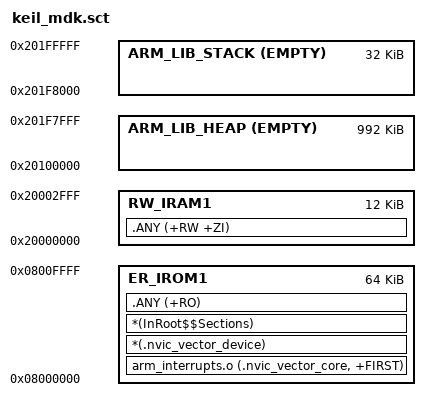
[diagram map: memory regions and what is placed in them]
; *************************************************************
; *** Scatter-Loading Description File generated by uVision ***
; *************************************************************


LR_IROM1 0x08000000 0x00010000  {    ; load region size_region
  ER_IROM1 0x08000000 0x00010000  {  ; load address = execution address
   arm_interrupts.o (.nvic_vector_core, +FIRST)
   *(.nvic_vector_device)
   *(InRoot$$Sections)
   .ANY (+RO)
  }
  RW_IRAM1 0x20000000 0x00003000  {  ; RW data
   .ANY (+RW +ZI)
  }
  ARM_LIB_HEAP 0x20100000 EMPTY 0x100000-0x8000 {} ; Heap starts at 1MB
  ARM_LIB_STACK 0x20200000 EMPTY -0x8000 {}
}
